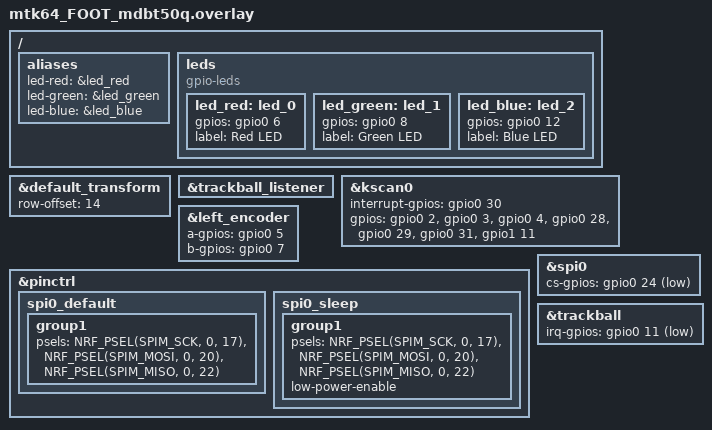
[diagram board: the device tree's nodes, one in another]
// Include base mtk64 configuration but override GPIO settings for MDBT50Q
#include "mtk64.dtsi"
#include "mtk64_trackball.dtsi"

&default_transform {
    row-offset = <14>;
};

&trackball_listener {
    status = "okay";  
};

// Override the kscan configuration from mtk64.dtsi with MDBT50Q GPIO pins
&kscan0 {
    // MDBT50Q GPIO mappings (using P0/P1 pins instead of xiao_d)
    interrupt-gpios = <&gpio0 30 (GPIO_ACTIVE_HIGH | GPIO_PULL_DOWN)>; // P0.30
    gpios = <&gpio0 2 GPIO_ACTIVE_HIGH>   // P0.02
          , <&gpio0 3 GPIO_ACTIVE_HIGH>   // P0.03
          , <&gpio0 4 GPIO_ACTIVE_HIGH>   // P0.04
          , <&gpio0 28 GPIO_ACTIVE_HIGH>  // P0.28
          , <&gpio0 29 GPIO_ACTIVE_HIGH>  // P0.29
          , <&gpio0 31 GPIO_ACTIVE_HIGH>  // P0.31
          , <&gpio1 11 GPIO_ACTIVE_HIGH>; // P1.11
};

// Override encoder configuration and enable it
&left_encoder {
    status = "okay";
    a-gpios = <&gpio0 5 (GPIO_ACTIVE_HIGH | GPIO_PULL_UP)>;  // P0.05
    b-gpios = <&gpio0 7 (GPIO_ACTIVE_HIGH | GPIO_PULL_UP)>;  // P0.07
};

// Override SPI configuration for MDBT50Q pins
&pinctrl {
    spi0_default: spi0_default {
        group1 {
            psels = <NRF_PSEL(SPIM_SCK, 0, 17)>,   // P0.17 for SCK
                <NRF_PSEL(SPIM_MOSI, 0, 20)>,      // P0.20 for MOSI
                <NRF_PSEL(SPIM_MISO, 0, 22)>;      // P0.22 for MISO
        };
    };

    spi0_sleep: spi0_sleep {
        group1 {
            psels = <NRF_PSEL(SPIM_SCK, 0, 17)>,
                <NRF_PSEL(SPIM_MOSI, 0, 20)>,
                <NRF_PSEL(SPIM_MISO, 0, 22)>;
            low-power-enable;
        };
    };
};

// Enable SPI and trackball
&spi0 {
    status = "okay";
    cs-gpios = <&gpio0 24 GPIO_ACTIVE_LOW>; // P0.24 for CS
};

&trackball {
    status = "okay";
    irq-gpios = <&gpio0 11 (GPIO_ACTIVE_LOW | GPIO_PULL_UP)>; // P0.11 for interrupt
};

/ {
    // Add LED aliases for RGB widget compatibility
    aliases {
        led-red = &led_red;
        led-green = &led_green; 
        led-blue = &led_blue;
    };

    // Define individual LED nodes for RGB widget
    leds {
        compatible = "gpio-leds";
        led_red: led_0 {
            gpios = <&gpio0 6 GPIO_ACTIVE_HIGH>; // P0.06 for red LED
            label = "Red LED";
        };
        led_green: led_1 {
            gpios = <&gpio0 8 GPIO_ACTIVE_HIGH>; // P0.08 for green LED
            label = "Green LED";
        };
        led_blue: led_2 {
            gpios = <&gpio0 12 GPIO_ACTIVE_HIGH>; // P0.12 for blue LED
            label = "Blue LED";
        };
    };
};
